# ATSAMC21N18A register map
Registers are 32-bit, access not given, no defined reset value unless marked. A register's access mark holds for its fields unless they carry their own. Addresses are absolute; registers are grouped by the start of their names; [hi:lo] are bit positions.

## SDADC
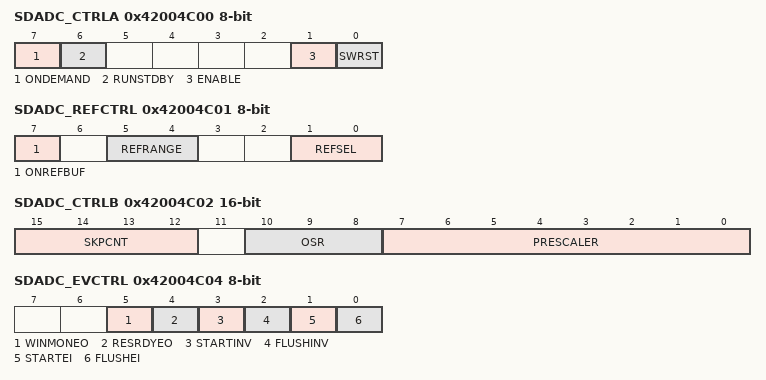
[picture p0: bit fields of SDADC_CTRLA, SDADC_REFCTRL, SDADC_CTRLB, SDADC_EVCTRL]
0x42004C00 SDADC_CTRLA 8-bit — Control A
  [7] ONDEMAND, [6] RUNSTDBY, [1] ENABLE, [0] SWRST
0x42004C01 SDADC_REFCTRL 8-bit — Reference Control
  [7] ONREFBUF, [5:4] REFRANGE, [1:0] REFSEL
0x42004C02 SDADC_CTRLB 16-bit — Control B
  [15:12] SKPCNT, [10:8] OSR, [7:0] PRESCALER
0x42004C04 SDADC_EVCTRL 8-bit — Event Control
  [5] WINMONEO, [4] RESRDYEO, [3] STARTINV, [2] FLUSHINV, [1] STARTEI, [0] FLUSHEI
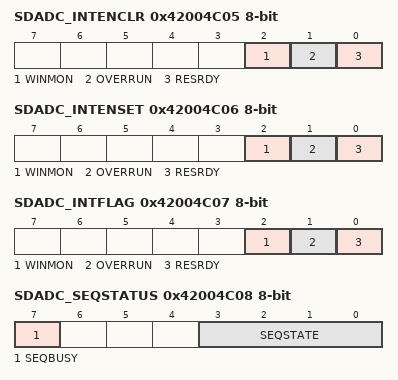
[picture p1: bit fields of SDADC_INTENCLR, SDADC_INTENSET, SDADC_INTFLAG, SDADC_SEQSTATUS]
0x42004C05 SDADC_INTENCLR 8-bit — Interrupt Enable Clear
  [2] WINMON, [1] OVERRUN, [0] RESRDY
0x42004C06 SDADC_INTENSET 8-bit — Interrupt Enable Set
  [2] WINMON, [1] OVERRUN, [0] RESRDY
0x42004C07 SDADC_INTFLAG 8-bit — Interrupt Flag Status and Clear
  [2] WINMON, [1] OVERRUN, [0] RESRDY
0x42004C08 SDADC_SEQSTATUS 8-bit — Sequence Status
  [7] SEQBUSY, [3:0] SEQSTATE
0x42004C09 SDADC_INPUTCTRL 8-bit — Input Control
  [3:0] MUXSEL
0x42004C0A SDADC_CTRLC 8-bit — Control C
  [0] FREERUN
0x42004C0B SDADC_WINCTRL 8-bit — Window Monitor Control
  [2:0] WINMODE
0x42004C0C SDADC_WINLT — Window Monitor Lower Threshold
  [23:0] WINLT
0x42004C10 SDADC_WINUT — Window Monitor Upper Threshold
  [23:0] WINUT
0x42004C14 SDADC_OFFSETCORR — Offset Correction
  [23:0] OFFSETCORR
0x42004C18 SDADC_GAINCORR 16-bit — Gain Correction
  [13:0] GAINCORR
0x42004C1A SDADC_SHIFTCORR 8-bit — Shift Correction
  [3:0] SHIFTCORR
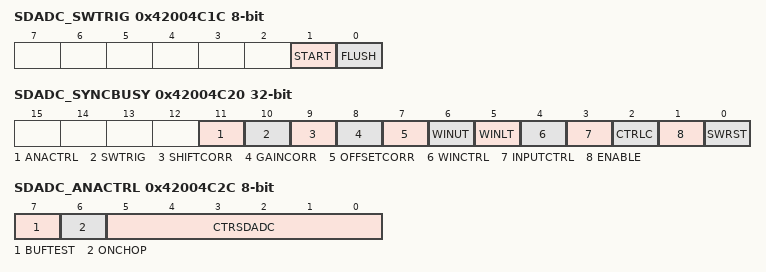
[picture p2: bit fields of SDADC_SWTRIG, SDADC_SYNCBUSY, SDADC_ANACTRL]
0x42004C1C SDADC_SWTRIG 8-bit — Software Trigger
  [1] START, [0] FLUSH
0x42004C20 SDADC_SYNCBUSY — Synchronization Busy
  [11] ANACTRL, [10] SWTRIG, [9] SHIFTCORR, [8] GAINCORR, [7] OFFSETCORR, [6] WINUT, [5] WINLT, [4] WINCTRL, [3] INPUTCTRL, [2] CTRLC, [1] ENABLE, [0] SWRST
0x42004C24 SDADC_RESULT — Result
  [23:0] RESULT
0x42004C28 SDADC_SEQCTRL 8-bit — Sequence Control
  [2:0] SEQEN
0x42004C2C SDADC_ANACTRL 8-bit — Analog Control
  [7] BUFTEST, [6] ONCHOP, [5:0] CTRSDADC
0x42004C2E SDADC_DBGCTRL 8-bit — Debug Control
  [0] DBGRUN

## SUPC
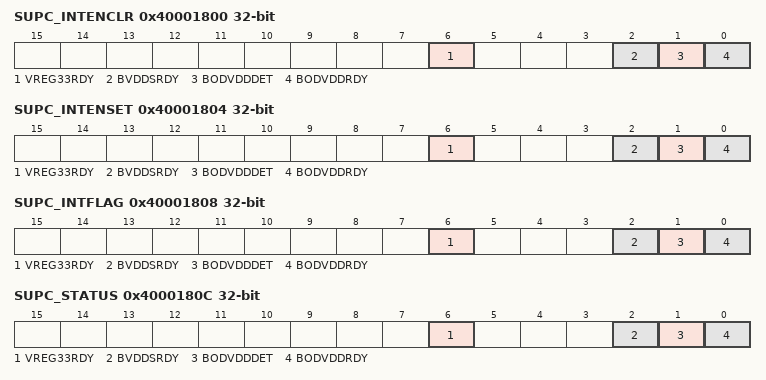
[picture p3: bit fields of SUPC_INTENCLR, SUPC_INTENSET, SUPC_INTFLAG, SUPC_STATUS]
0x40001800 SUPC_INTENCLR — Interrupt Enable Clear
  [6] VREG33RDY, [2] BVDDSRDY, [1] BODVDDDET, [0] BODVDDRDY
0x40001804 SUPC_INTENSET — Interrupt Enable Set
  [6] VREG33RDY, [2] BVDDSRDY, [1] BODVDDDET, [0] BODVDDRDY
0x40001808 SUPC_INTFLAG — Interrupt Flag Status and Clear
  [6] VREG33RDY, [2] BVDDSRDY, [1] BODVDDDET, [0] BODVDDRDY
0x4000180C SUPC_STATUS — Power and Clocks Status
  [6] VREG33RDY, [2] BVDDSRDY, [1] BODVDDDET, [0] BODVDDRDY
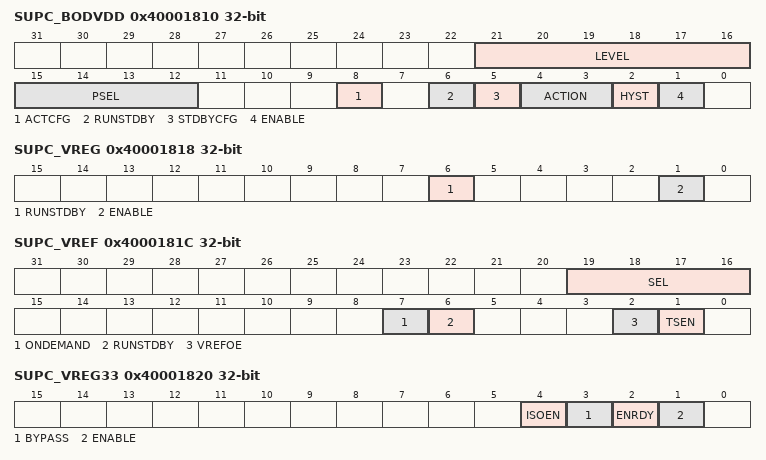
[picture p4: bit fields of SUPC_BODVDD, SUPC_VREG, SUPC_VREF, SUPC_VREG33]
0x40001810 SUPC_BODVDD — BODVDD Control
  [21:16] LEVEL, [15:12] PSEL, [8] ACTCFG, [6] RUNSTDBY, [5] STDBYCFG, [4:3] ACTION, [2] HYST, [1] ENABLE
0x40001818 SUPC_VREG — VREG Control
  [6] RUNSTDBY, [1] ENABLE
0x4000181C SUPC_VREF — VREF Control
  [19:16] SEL, [7] ONDEMAND, [6] RUNSTDBY, [2] VREFOE, [1] TSEN
0x40001820 SUPC_VREG33 — VREG33 Control
  [4] ISOEN, [3] BYPASS, [2] ENRDY, [1] ENABLE

## TC0
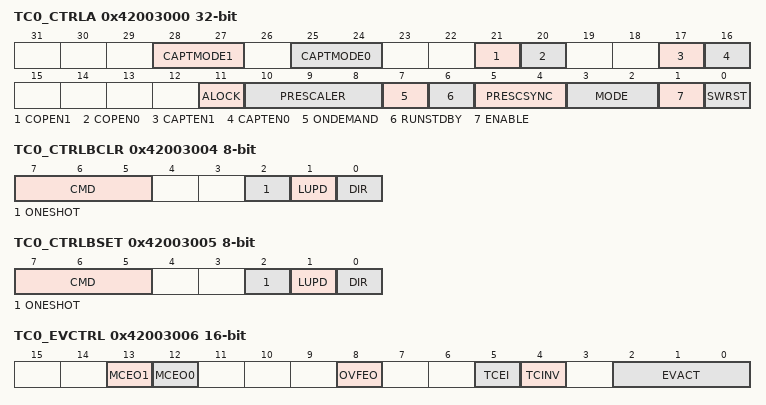
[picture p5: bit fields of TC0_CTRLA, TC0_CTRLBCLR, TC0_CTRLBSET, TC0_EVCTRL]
0x42003000 TC0_CTRLA — Control A
  [28:27] CAPTMODE1, [25:24] CAPTMODE0, [21] COPEN1, [20] COPEN0, [17] CAPTEN1, [16] CAPTEN0, [11] ALOCK, [10:8] PRESCALER, [7] ONDEMAND, [6] RUNSTDBY, [5:4] PRESCSYNC, [3:2] MODE, [1] ENABLE, [0] SWRST
0x42003004 TC0_CTRLBCLR 8-bit — Control B Clear
  [7:5] CMD, [2] ONESHOT, [1] LUPD, [0] DIR
0x42003005 TC0_CTRLBSET 8-bit — Control B Set
  [7:5] CMD, [2] ONESHOT, [1] LUPD, [0] DIR
0x42003006 TC0_EVCTRL 16-bit — Event Control
  [13] MCEO1, [12] MCEO0, [8] OVFEO, [5] TCEI, [4] TCINV, [2:0] EVACT
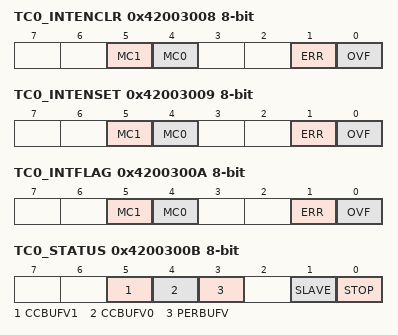
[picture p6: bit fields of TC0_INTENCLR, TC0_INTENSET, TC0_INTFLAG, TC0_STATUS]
0x42003008 TC0_INTENCLR 8-bit — Interrupt Enable Clear
  [5] MC1, [4] MC0, [1] ERR, [0] OVF
0x42003009 TC0_INTENSET 8-bit — Interrupt Enable Set
  [5] MC1, [4] MC0, [1] ERR, [0] OVF
0x4200300A TC0_INTFLAG 8-bit — Interrupt Flag Status and Clear
  [5] MC1, [4] MC0, [1] ERR, [0] OVF
0x4200300B TC0_STATUS 8-bit — Status
  [5] CCBUFV1, [4] CCBUFV0, [3] PERBUFV, [1] SLAVE, [0] STOP
0x4200300C TC0_WAVE 8-bit — Waveform Generation Control
  [1:0] WAVEGEN
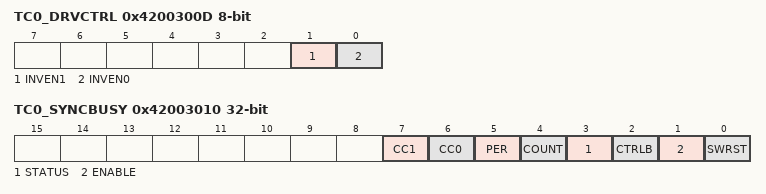
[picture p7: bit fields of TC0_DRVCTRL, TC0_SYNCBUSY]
0x4200300D TC0_DRVCTRL 8-bit — Control C
  [1] INVEN1, [0] INVEN0
0x4200300F TC0_DBGCTRL 8-bit — Debug Control
  [0] DBGRUN
0x42003010 TC0_SYNCBUSY — Synchronization Status
  [7] CC1, [6] CC0, [5] PER, [4] COUNT, [3] STATUS, [2] CTRLB, [1] ENABLE, [0] SWRST
0x42003014 TC0_COUNT_COUNT8 8-bit — COUNT8 Count
  [7:0] COUNT — Counter Value
0x42003014 TC0_COUNT_COUNT16 16-bit — COUNT16 Count
  [15:0] COUNT — Counter Value
0x42003014 TC0_COUNT_COUNT32 — COUNT32 Count
  [31:0] COUNT — Counter Value
0x4200301B TC0_PER_COUNT8 8-bit — COUNT8 Period
  [7:0] PER — Period Value
0x4200301C TC0_CC_COUNT8 8-bit — COUNT8 Compare and Capture
  [7:0] CC — Counter/Compare Value
0x4200301C TC0_CC_COUNT16 16-bit — COUNT16 Compare and Capture
  [15:0] CC — Counter/Compare Value
0x4200301C TC0_CC_COUNT32 — COUNT32 Compare and Capture
  [31:0] CC — Counter/Compare Value
0x4200302F TC0_PERBUF_COUNT8 8-bit — COUNT8 Period Buffer
  [7:0] PERBUF — Period Buffer Value
0x42003030 TC0_CCBUF_COUNT8 8-bit — COUNT8 Compare and Capture Buffer
  [7:0] CCBUF — Counter/Compare Buffer Value
0x42003030 TC0_CCBUF_COUNT16 16-bit — COUNT16 Compare and Capture Buffer
  [15:0] CCBUF — Counter/Compare Buffer Value
0x42003030 TC0_CCBUF_COUNT32 — COUNT32 Compare and Capture Buffer
  [31:0] CCBUF — Counter/Compare Buffer Value
